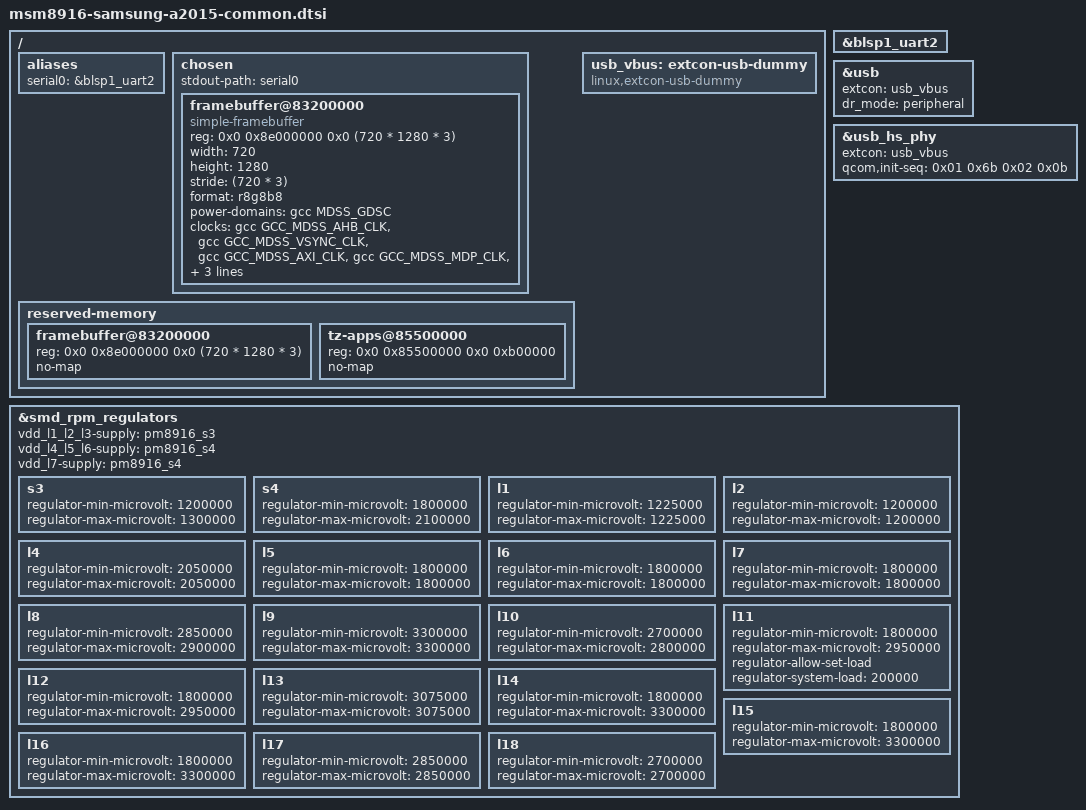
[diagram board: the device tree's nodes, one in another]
// SPDX-License-Identifier: GPL-2.0-only

#include "msm8916-pm8916.dtsi"
#include "msm8916-no-psci.dtsi"
#include <dt-bindings/gpio/gpio.h>
#include <dt-bindings/input/input.h>
#include <dt-bindings/interrupt-controller/irq.h>
#include <dt-bindings/sound/apq8016-lpass.h>

/ {
	aliases {
		serial0 = &blsp1_uart2;
	};

	chosen {
		stdout-path = "serial0";

		#address-cells = <2>;
		#size-cells = <2>;
		ranges;

		framebuffer@83200000 {
			compatible = "simple-framebuffer";
			reg = <0x0 0x8e000000 0x0 (720 * 1280 * 3)>;
			width = <720>;
			height = <1280>;
			stride = <(720 * 3)>;
			format = "r8g8b8";
			power-domains = <&gcc MDSS_GDSC>;
			clocks = <&gcc GCC_MDSS_AHB_CLK>,
				 <&gcc GCC_MDSS_VSYNC_CLK>,
				 <&gcc GCC_MDSS_AXI_CLK>,
				 <&gcc GCC_MDSS_MDP_CLK>,
				 <&gcc GCC_MDSS_BYTE0_CLK>,
				 <&gcc GCC_MDSS_PCLK0_CLK>,
				 <&gcc GCC_MDSS_ESC0_CLK>;
		};
	};

	reserved-memory {
		framebuffer@83200000 {
			reg = <0x0 0x8e000000 0x0 (720 * 1280 * 3)>;
			no-map;
		};

		/* Additional memory used by Samsung firmware modifications */
		tz-apps@85500000 {
			reg = <0x0 0x85500000 0x0 0xb00000>;
			no-map;
		};
	};

	usb_vbus: extcon-usb-dummy {
		compatible = "linux,extcon-usb-dummy";
	};
};

&blsp1_uart2 {
	status = "okay";
};

&usb {
	status = "okay";
	extcon = <&usb_vbus>;
	dr_mode = "peripheral";
};

&usb_hs_phy {
	extcon = <&usb_vbus>;
	qcom,init-seq = /bits/ 8 <0x01 0x6b 0x02 0x0b>;
};

&smd_rpm_regulators {
	vdd_l1_l2_l3-supply = <&pm8916_s3>;
	vdd_l4_l5_l6-supply = <&pm8916_s4>;
	vdd_l7-supply = <&pm8916_s4>;

	s3 {
		regulator-min-microvolt = <1200000>;
		regulator-max-microvolt = <1300000>;
	};

	s4 {
		regulator-min-microvolt = <1800000>;
		regulator-max-microvolt = <2100000>;
	};

	l1 {
		regulator-min-microvolt = <1225000>;
		regulator-max-microvolt = <1225000>;
	};

	l2 {
		regulator-min-microvolt = <1200000>;
		regulator-max-microvolt = <1200000>;
	};

	l4 {
		regulator-min-microvolt = <2050000>;
		regulator-max-microvolt = <2050000>;
	};

	l5 {
		regulator-min-microvolt = <1800000>;
		regulator-max-microvolt = <1800000>;
	};

	l6 {
		regulator-min-microvolt = <1800000>;
		regulator-max-microvolt = <1800000>;
	};

	l7 {
		regulator-min-microvolt = <1800000>;
		regulator-max-microvolt = <1800000>;
	};

	l8 {
		regulator-min-microvolt = <2850000>;
		regulator-max-microvolt = <2900000>;
	};

	l9 {
		regulator-min-microvolt = <3300000>;
		regulator-max-microvolt = <3300000>;
	};

	l10 {
		regulator-min-microvolt = <2700000>;
		regulator-max-microvolt = <2800000>;
	};

	l11 {
		regulator-min-microvolt = <1800000>;
		regulator-max-microvolt = <2950000>;
		regulator-allow-set-load;
		regulator-system-load = <200000>;
	};

	l12 {
		regulator-min-microvolt = <1800000>;
		regulator-max-microvolt = <2950000>;
	};

	l13 {
		regulator-min-microvolt = <3075000>;
		regulator-max-microvolt = <3075000>;
	};

	l14 {
		regulator-min-microvolt = <1800000>;
		regulator-max-microvolt = <3300000>;
	};

	l15 {
		regulator-min-microvolt = <1800000>;
		regulator-max-microvolt = <3300000>;
	};

	l16 {
		regulator-min-microvolt = <1800000>;
		regulator-max-microvolt = <3300000>;
	};

	l17 {
		regulator-min-microvolt = <2850000>;
		regulator-max-microvolt = <2850000>;
	};

	l18 {
		regulator-min-microvolt = <2700000>;
		regulator-max-microvolt = <2700000>;
	};
};
